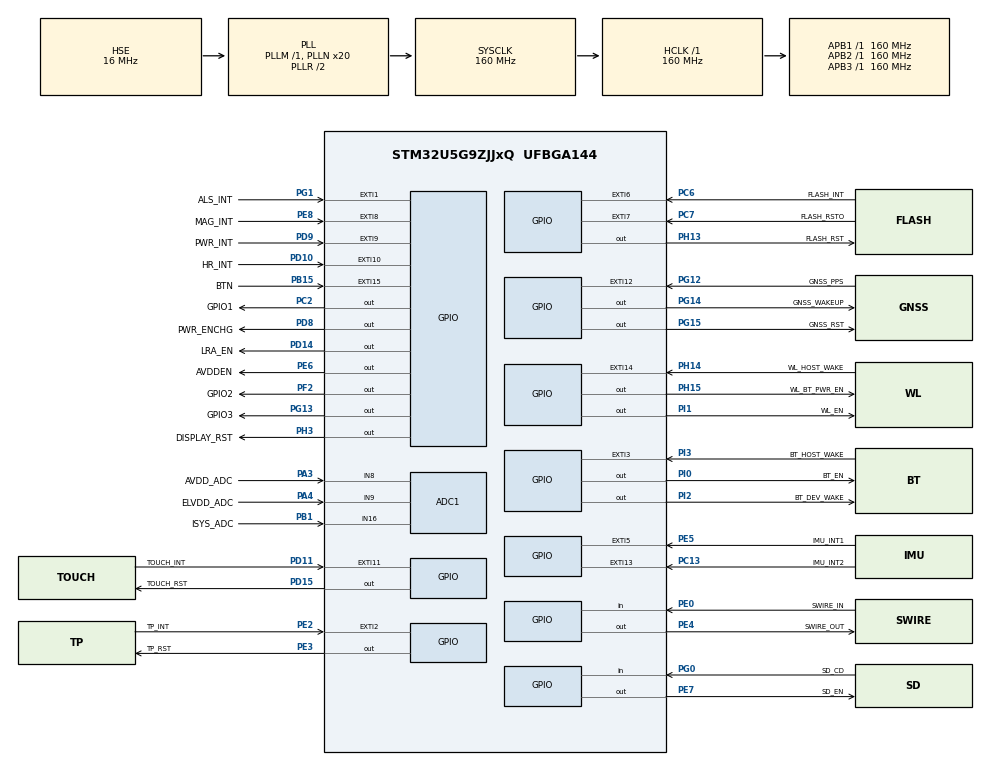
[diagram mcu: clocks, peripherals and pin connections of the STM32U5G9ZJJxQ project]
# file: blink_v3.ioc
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ADC1.Channel-0\#ChannelRegularConversion=ADC_CHANNEL_8
ADC1.MonitoredBy-0\#ChannelRegularConversion=__NULL
ADC1.NbrOfConversionFlag=1
ADC1.OffsetNumber-0\#ChannelRegularConversion=ADC_OFFSET_NONE
ADC1.Rank-0\#ChannelRegularConversion=1
ADC1.SamplingTime-0\#ChannelRegularConversion=ADC_SAMPLETIME_5CYCLE
ADC1.master=1
CORTEX_M33_NS.userName=CORTEX_M33
DSI_CKN.PinAttribute=Free
DSI_CKN.Signal=DSIHOST_CKN
DSI_CKP.PinAttribute=Free
DSI_CKP.Signal=DSIHOST_CKP
DSI_D0N.PinAttribute=Free
DSI_D0N.Signal=DSIHOST_D0N
DSI_D0P.PinAttribute=Free
DSI_D0P.Signal=DSIHOST_D0P
DSI_D1N.PinAttribute=Free
DSI_D1N.Signal=DSIHOST_D1N
DSI_D1P.PinAttribute=Free
DSI_D1P.Signal=DSIHOST_D1P
Mcu.Family=STM32U5
Mcu.Name=STM32U5G9ZJJxQ
Mcu.Package=UFBGA144
NVIC.PriorityGroup=NVIC_PRIORITYGROUP_4
NVIC.TIM6_IRQn=true\:15\:0\:false\:false\:true\:false\:true\:true
NVIC.TimeBase=TIM6_IRQn
NVIC.TimeBaseIP=TIM6
PA0.PinAttribute=Free
PA0.Signal=UART4_TX
PA1.PinAttribute=Free
PA1.Signal=UART4_RX
PA11.Signal=USB_OTG_HS_DM
PA12.Signal=USB_OTG_HS_DP
PA13\ (JTMS/SWDIO).Mode=Serial_Wire
PA13\ (JTMS/SWDIO).Signal=DEBUG_JTMS-SWDIO
PA14\ (JTCK/SWCLK).Mode=Serial_Wire
PA14\ (JTCK/SWCLK).Signal=DEBUG_JTCK-SWCLK
PA15\ (JTDI).Signal=USART2_RX
PA2.Mode=Clock-out-LSCO
PA2.Signal=RCC_LSCO
PA3.GPIO_Label=AVDD_ADC
PA3.Mode=IN8-Single-Ended
PA3.Signal=ADC1_IN8
PA4.GPIO_Label=ELVDD_ADC
PA4.Mode=IN9-Single-Ended
PA4.Signal=ADC1_IN9
PA5.PinAttribute=Free
PA5.Signal=SPI1_SCK
PA6.Signal=SPI1_MISO
PA7.Signal=SPI1_MOSI
PA8.Signal=SDMMC2_D1
PB0.PinAttribute=Free
PB0.Signal=SPI1_NSS
PB1.GPIO_Label=ISYS_ADC
PB1.Mode=IN16-Single-Ended
PB1.Signal=ADC1_IN16
PB10.Signal=OCTOSPIM_P1_CLK
PB11.PinAttribute=Free
PB11.Signal=I2C2_SDA
PB13.Signal=I2C2_SCL
PB14.PinAttribute=Free
PB14.Signal=SDMMC2_D0
PB15.GPIO_Label=BTN
PB15.Signal=GPXTI15
PB2.PinAttribute=Free
PB2.Signal=OCTOSPIM_P1_DQS
PB3\ (JTDO/TRACESWO).Signal=SDMMC2_D2
PB4\ (NJTRST).PinAttribute=Free
PB4\ (NJTRST).Signal=SDMMC2_D3
PB5.Signal=OCTOSPIM_P1_NCLK
PB6.PinAttribute=Free
PB6.Signal=I2C1_SCL
PB7.Signal=DSIHOST_TE
PB8.Signal=SDMMC1_CKIN
PB9.Signal=I2C1_SDA
PC0.PinAttribute=Free
PC0.Signal=I2C3_SCL
PC1.PinAttribute=Free
PC1.Signal=I2C3_SDA
PC10.Signal=SDMMC1_D2
PC11.Signal=SDMMC1_D3
PC12.PinAttribute=Free
PC12.Signal=SDMMC1_CK
PC13.GPIO_Label=IMU_INT2
PC13.PinAttribute=Free
PC13.Signal=GPXTI13
PC14-OSC32_IN\ (PC14).Mode=LSE-External-Oscillator
PC14-OSC32_IN\ (PC14).Signal=RCC_OSC32_IN
PC15-OSC32_OUT\ (PC15).Mode=LSE-External-Oscillator
PC15-OSC32_OUT\ (PC15).Signal=RCC_OSC32_OUT
PC2.GPIO_Label=GPIO1
PC2.PinAttribute=Free
PC2.Signal=GPIO_Output
PC3.GPIO_Label=ELVSS_ADC
PC3.Signal=ADC1_IN4
PC6.GPIO_Label=FLASH_INT
PC6.PinAttribute=Free
PC6.Signal=GPXTI6
PC7.GPIO_Label=FLASH_RSTO
PC7.PinAttribute=Free
PC7.Signal=GPXTI7
PC8.Signal=SDMMC1_D0
PC9.PinAttribute=Free
PC9.Signal=SDMMC1_D1
PD0.Signal=I2C5_SDA
PD1.PinAttribute=Free
PD1.Signal=I2C5_SCL
PD10.GPIO_Label=HR_INT
PD10.PinAttribute=Free
PD10.Signal=GPXTI10
PD11.GPIO_Label=TOUCH_INT
PD11.PinAttribute=Free
PD11.Signal=GPXTI11
PD12.Signal=I2C4_SCL
PD13.Signal=I2C4_SDA
PD14.GPIO_Label=LRA_EN
PD14.Signal=GPIO_Output
PD15.GPIO_Label=TOUCH_RST
PD15.GPIO_ModeDefaultOutputPP=GPIO_MODE_OUTPUT_OD
PD15.GPIO_PuPd=GPIO_NOPULL
PD15.PinAttribute=Free
PD15.Signal=GPIO_Output
PD2.Signal=SDMMC1_CMD
PD3.PinAttribute=Free
PD3.Signal=USART2_CTS
PD4.Signal=USART2_RTS
PD5.Signal=USART2_TX
PD6.Signal=SDMMC2_CK
PD7.PinAttribute=Free
PD7.Signal=SDMMC2_CMD
PD8.GPIO_Label=PWR_ENCHG
PD8.Signal=GPIO_Output
PD9.GPIO_Label=PWR_INT
PD9.Signal=GPXTI9
PE0.GPIO_Label=SWIRE_IN
PE0.PinAttribute=Free
PE0.Signal=GPIO_Input
PE10.PinAttribute=Free
PE10.Signal=ADF1_SDI0
PE11.Signal=OCTOSPIM_P1_NCS
PE12.PinAttribute=Free
PE12.Signal=OCTOSPIM_P1_IO0
PE13.Signal=OCTOSPIM_P1_IO1
PE14.PinAttribute=Free
PE14.Signal=OCTOSPIM_P1_IO2
PE15.Signal=OCTOSPIM_P1_IO3
PE2.GPIO_Label=TP_INT
PE2.PinAttribute=Free
PE2.Signal=GPXTI2
PE3.GPIO_Label=TP_RST
PE3.PinAttribute=Free
PE3.Signal=GPIO_Output
PE4.GPIO_Label=SWIRE_OUT
PE4.Signal=GPIO_Output
PE5.GPIO_Label=IMU_INT1
PE5.Signal=GPXTI5
PE6.GPIO_Label=AVDDEN
PE6.Signal=GPIO_Output
PE7.GPIO_Label=SD_EN
PE7.Signal=GPIO_Output
PE8.GPIO_Label=MAG_INT
PE8.PinAttribute=Free
PE8.Signal=GPXTI8
PE9.PinAttribute=Free
PE9.Signal=ADF1_CCK0
PF0.PinAttribute=Free
PF0.Signal=I2C6_SDA
PF1.PinAttribute=Free
PF1.Signal=I2C6_SCL
PF2.GPIO_Label=GPIO2
PF2.PinAttribute=Free
PF2.Signal=GPIO_Output
PG0.GPIO_Label=SD_CD
PG0.PinAttribute=Free
PG0.Signal=GPIO_Input
PG1.GPIO_Label=ALS_INT
PG1.PinAttribute=Free
PG1.Signal=GPXTI1
PG10.PinAttribute=Free
PG10.Signal=USART1_RX
PG12.GPIO_Label=GNSS_PPS
PG12.PinAttribute=Free
PG12.Signal=GPXTI12
PG13.GPIO_Label=GPIO3
PG13.Signal=GPIO_Output
PG14.GPIO_Label=GNSS_WAKEUP
PG14.PinAttribute=Free
PG14.Signal=GPIO_Output
PG15.GPIO_Label=GNSS_RST
PG15.Signal=GPIO_Output
PG9.Signal=USART1_TX
PH0-OSC_IN\ (PH0).Mode=HSE-External-Oscillator
PH0-OSC_IN\ (PH0).PinAttribute=Free
PH0-OSC_IN\ (PH0).Signal=RCC_OSC_IN
PH1-OSC_OUT\ (PH1).Mode=HSE-External-Oscillator
PH1-OSC_OUT\ (PH1).PinAttribute=Free
PH1-OSC_OUT\ (PH1).Signal=RCC_OSC_OUT
PH10.PinAttribute=Free
PH10.Signal=OCTOSPIM_P2_IO5
PH11.PinAttribute=Free
PH11.Signal=OCTOSPIM_P2_IO6
PH12.PinAttribute=Free
PH12.Signal=OCTOSPIM_P2_IO7
PH13.GPIO_Label=FLASH_RST
PH13.PinAttribute=Free
PH13.Signal=GPIO_Output
PH14.GPIO_Label=WL_HOST_WAKE
PH14.PinAttribute=Free
PH14.Signal=GPXTI14
PH15.GPIO_Label=WL_BT_PWR_EN
PH15.PinAttribute=Free
PH15.Signal=GPIO_Output
PH3-BOOT0.GPIO_Label=DISPLAY_RST
PH3-BOOT0.PinAttribute=Free
PH3-BOOT0.Signal=GPIO_Output
PH9.Signal=OCTOSPIM_P2_IO4
PI0.GPIO_Label=BT_EN
PI0.PinAttribute=Free
PI0.Signal=GPIO_Output
PI1.GPIO_Label=WL_EN
PI1.PinAttribute=Free
PI1.Signal=GPIO_Output
PI2.GPIO_Label=BT_DEV_WAKE
PI2.PinAttribute=Free
PI2.Signal=GPIO_Output
PI3.GPIO_Label=BT_HOST_WAKE
PI3.PinAttribute=Free
PI3.Signal=GPXTI3
PWR.PowerMode=PWR_SMPS_SUPPLY
ProjectManager.HeapSize=0x200
ProjectManager.StackSize=0x400
ProjectManager.TargetToolchain=STM32CubeIDE
RCC.ADCFreq_Value=16000000
RCC.AHBFreq_Value=160000000
RCC.APB1Freq_Value=160000000
RCC.APB1TimFreq_Value=160000000
RCC.APB2Freq_Value=160000000
RCC.APB2TimFreq_Value=160000000
RCC.APB3Freq_Value=160000000
RCC.CortexFreq_Value=160000000
RCC.EPOD_VALUE=16000000
RCC.FLatency=FLASH_LATENCY_2
RCC.HCLKFreq_Value=160000000
RCC.HSE_VALUE=16000000
RCC.HSI48_VALUE=48000000
RCC.HSI_VALUE=16000000
RCC.LSCOSource1Virtual=RCC_LSCOSOURCE_LSE
RCC.LSIDIV_VALUE=32000
RCC.MSI_VALUE=4000000
RCC.PLL2Source=RCC_PLLSOURCE_HSE
RCC.PLL3Source=RCC_PLLSOURCE_HSE
RCC.PLLN=20
RCC.PLLSourceVirtual=RCC_PLLSOURCE_HSE
RCC.RTCClockSelection=RCC_RTCCLKSOURCE_LSE
RCC.SYSCLKFreq_VALUE=160000000
RCC.SYSCLKSource=RCC_SYSCLKSOURCE_PLLCLK
RCC.VCOOutputFreq_Value=320000000
RCC.VDD_VALUE=1.8
VP_DCACHE1_VS_DCACHE.Mode=DCACHE_Activate
VP_DCACHE2_VS_DCACHE.Mode=DCACHE_Activate
VP_ICACHE_VS_ICACHE.Mode=DefaultMode
VP_LPBAMQUEUE_VS_QUEUE.Mode=QUEUEMODE
VP_LPBAM_VS_SIG1.Mode=SmartRun
VP_LPBAM_VS_SIG4.Mode=LPDMA1
VP_MEMORYMAP_VS_MEMORYMAP.Mode=CurAppReg
VP_PWR_VS_LPOM.Mode=PowerOptimisation
VP_PWR_VS_SECSignals.Mode=Security/Privilege
VP_PWR_Vdda.Mode=isolationVdda
VP_RTC_VS_RTC_Activate.Mode=RTC_Enabled
VP_SYS_VS_tim6.Mode=TIM6
VREF+.Mode=InternalMode
VREF+.PinAttribute=Free
VREF+.Signal=VREFBUF_OUT
board=custom

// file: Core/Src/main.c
/* USER CODE BEGIN Header */
/**
  ******************************************************************************
  * @file           : main.c
  * @brief          : Main program body
  ******************************************************************************
  * @attention
  *
  * Copyright (c) 2024 STMicroelectronics.
  * All rights reserved.
  *
  * This software is licensed under terms that can be found in the LICENSE file
  * in the root directory of this software component.
  * If no LICENSE file comes with this software, it is provided AS-IS.
  *
  ******************************************************************************
  */
/* USER CODE END Header */
#include "main.h"

ADC_HandleTypeDef hadc1;

DCACHE_HandleTypeDef hdcache1;
DCACHE_HandleTypeDef hdcache2;

RTC_HandleTypeDef hrtc;

void SystemClock_Config(void);
static void SystemPower_Config(void);
static void MX_GPIO_Init(void);
static void MX_DCACHE1_Init(void);
static void MX_DCACHE2_Init(void);
static void MX_ICACHE_Init(void);
static void MX_RTC_Init(void);
static void MX_ADC1_Init(void);

int main(void)
{

  /* MCU Configuration--------------------------------------------------------*/

  /* Reset of all peripherals, Initializes the Flash interface and the Systick. */
  HAL_Init();

  /* Configure the system clock */
  SystemClock_Config();

  /* Configure the System Power */
  SystemPower_Config();

  /* Initialize all configured peripherals */
  MX_GPIO_Init();
  MX_DCACHE1_Init();
  MX_DCACHE2_Init();
  MX_ICACHE_Init();
  MX_RTC_Init();
  MX_ADC1_Init();

  /* Infinite loop */
  /* USER CODE BEGIN WHILE */
  while (1)
  {
	  HAL_GPIO_TogglePin(GPIO1_GPIO_Port, GPIO1_Pin);
	  HAL_Delay(500);
    /* USER CODE END WHILE */

  }
}

void SystemClock_Config(void)
{
  RCC_OscInitTypeDef RCC_OscInitStruct = {0};
  RCC_ClkInitTypeDef RCC_ClkInitStruct = {0};

  /** Configure the main internal regulator output voltage
  */
  if (HAL_PWREx_ControlVoltageScaling(PWR_REGULATOR_VOLTAGE_SCALE1) != HAL_OK)
  {
    Error_Handler();
  }

  /** Configure LSE Drive Capability
  */
  HAL_PWR_EnableBkUpAccess();
  __HAL_RCC_LSEDRIVE_CONFIG(RCC_LSEDRIVE_LOW);

  /** Initializes the CPU, AHB and APB buses clocks
  */
  RCC_OscInitStruct.OscillatorType = RCC_OSCILLATORTYPE_HSI|RCC_OSCILLATORTYPE_HSE
                              |RCC_OSCILLATORTYPE_LSE;
  RCC_OscInitStruct.HSEState = RCC_HSE_ON;
  RCC_OscInitStruct.LSEState = RCC_LSE_ON;
  RCC_OscInitStruct.HSIState = RCC_HSI_ON;
  RCC_OscInitStruct.HSICalibrationValue = RCC_HSICALIBRATION_DEFAULT;
  RCC_OscInitStruct.PLL.PLLState = RCC_PLL_ON;
  RCC_OscInitStruct.PLL.PLLSource = RCC_PLLSOURCE_HSE;
  RCC_OscInitStruct.PLL.PLLMBOOST = RCC_PLLMBOOST_DIV1;
  RCC_OscInitStruct.PLL.PLLM = 1;
  RCC_OscInitStruct.PLL.PLLN = 20;
  RCC_OscInitStruct.PLL.PLLP = 2;
  RCC_OscInitStruct.PLL.PLLQ = 2;
  RCC_OscInitStruct.PLL.PLLR = 2;
  RCC_OscInitStruct.PLL.PLLRGE = RCC_PLLVCIRANGE_1;
  RCC_OscInitStruct.PLL.PLLFRACN = 0;
  if (HAL_RCC_OscConfig(&RCC_OscInitStruct) != HAL_OK)
  {
    Error_Handler();
  }

  /** Initializes the CPU, AHB and APB buses clocks
  */
  RCC_ClkInitStruct.ClockType = RCC_CLOCKTYPE_HCLK|RCC_CLOCKTYPE_SYSCLK
                              |RCC_CLOCKTYPE_PCLK1|RCC_CLOCKTYPE_PCLK2
                              |RCC_CLOCKTYPE_PCLK3;
  RCC_ClkInitStruct.SYSCLKSource = RCC_SYSCLKSOURCE_PLLCLK;
  RCC_ClkInitStruct.AHBCLKDivider = RCC_SYSCLK_DIV1;
  RCC_ClkInitStruct.APB1CLKDivider = RCC_HCLK_DIV1;
  RCC_ClkInitStruct.APB2CLKDivider = RCC_HCLK_DIV1;
  RCC_ClkInitStruct.APB3CLKDivider = RCC_HCLK_DIV1;

  if (HAL_RCC_ClockConfig(&RCC_ClkInitStruct, FLASH_LATENCY_2) != HAL_OK)
  {
    Error_Handler();
  }

  /** LSCO configuration
  */
  HAL_RCCEx_EnableLSCO(RCC_LSCOSOURCE_LSE);
}

/**
  * @brief Power Configuration
  * @retval None
  */
static void SystemPower_Config(void)
{
  HAL_PWREx_EnableVddIO2();

  /*
   * Switch to SMPS regulator instead of LDO
   */
  if (HAL_PWREx_ConfigSupply(PWR_SMPS_SUPPLY) != HAL_OK)
  {
    Error_Handler();
  }
}

static void MX_ADC1_Init(void)
{

  ADC_ChannelConfTypeDef sConfig = {0};

  /** Common config
  */
  hadc1.Instance = ADC1;
  hadc1.Init.ClockPrescaler = ADC_CLOCK_ASYNC_DIV1;
  hadc1.Init.Resolution = ADC_RESOLUTION_14B;
  hadc1.Init.GainCompensation = 0;
  hadc1.Init.DataAlign = ADC_DATAALIGN_RIGHT;
  hadc1.Init.ScanConvMode = ADC_SCAN_DISABLE;
  hadc1.Init.EOCSelection = ADC_EOC_SINGLE_CONV;
  hadc1.Init.LowPowerAutoWait = DISABLE;
  hadc1.Init.ContinuousConvMode = DISABLE;
  hadc1.Init.NbrOfConversion = 1;
  hadc1.Init.DiscontinuousConvMode = DISABLE;
  hadc1.Init.ExternalTrigConv = ADC_SOFTWARE_START;
  hadc1.Init.ExternalTrigConvEdge = ADC_EXTERNALTRIGCONVEDGE_NONE;
  hadc1.Init.DMAContinuousRequests = DISABLE;
  hadc1.Init.TriggerFrequencyMode = ADC_TRIGGER_FREQ_HIGH;
  hadc1.Init.Overrun = ADC_OVR_DATA_PRESERVED;
  hadc1.Init.LeftBitShift = ADC_LEFTBITSHIFT_NONE;
  hadc1.Init.ConversionDataManagement = ADC_CONVERSIONDATA_DR;
  hadc1.Init.OversamplingMode = DISABLE;
  if (HAL_ADC_Init(&hadc1) != HAL_OK)
  {
    Error_Handler();
  }

  /** Configure Regular Channel
  */
  sConfig.Channel = ADC_CHANNEL_8;
  sConfig.Rank = ADC_REGULAR_RANK_1;
  sConfig.SamplingTime = ADC_SAMPLETIME_5CYCLE;
  sConfig.SingleDiff = ADC_SINGLE_ENDED;
  sConfig.OffsetNumber = ADC_OFFSET_NONE;
  sConfig.Offset = 0;
  if (HAL_ADC_ConfigChannel(&hadc1, &sConfig) != HAL_OK)
  {
    Error_Handler();
  }

}

static void MX_DCACHE1_Init(void)
{

  hdcache1.Instance = DCACHE1;
  hdcache1.Init.ReadBurstType = DCACHE_READ_BURST_WRAP;
  if (HAL_DCACHE_Init(&hdcache1) != HAL_OK)
  {
    Error_Handler();
  }

}

static void MX_DCACHE2_Init(void)
{

  hdcache2.Instance = DCACHE2;
  hdcache2.Init.ReadBurstType = DCACHE_READ_BURST_WRAP;
  if (HAL_DCACHE_Init(&hdcache2) != HAL_OK)
  {
    Error_Handler();
  }
   __HAL_RCC_SYSCFG_CLK_ENABLE();
   HAL_SYSCFG_DisableSRAMCached();

}

static void MX_ICACHE_Init(void)
{

  /** Enable instruction cache (default 2-ways set associative cache)
  */
  if (HAL_ICACHE_Enable() != HAL_OK)
  {
    Error_Handler();
  }

}

static void MX_RTC_Init(void)
{

  RTC_PrivilegeStateTypeDef privilegeState = {0};

  /** Initialize RTC Only
  */
  hrtc.Instance = RTC;
  hrtc.Init.HourFormat = RTC_HOURFORMAT_24;
  hrtc.Init.AsynchPrediv = 127;
  hrtc.Init.SynchPrediv = 255;
  hrtc.Init.OutPut = RTC_OUTPUT_DISABLE;
  hrtc.Init.OutPutRemap = RTC_OUTPUT_REMAP_NONE;
  hrtc.Init.OutPutPolarity = RTC_OUTPUT_POLARITY_HIGH;
  hrtc.Init.OutPutType = RTC_OUTPUT_TYPE_OPENDRAIN;
  hrtc.Init.OutPutPullUp = RTC_OUTPUT_PULLUP_NONE;
  hrtc.Init.BinMode = RTC_BINARY_NONE;
  if (HAL_RTC_Init(&hrtc) != HAL_OK)
  {
    Error_Handler();
  }
  privilegeState.rtcPrivilegeFull = RTC_PRIVILEGE_FULL_NO;
  privilegeState.backupRegisterPrivZone = RTC_PRIVILEGE_BKUP_ZONE_NONE;
  privilegeState.backupRegisterStartZone2 = RTC_BKP_DR0;
  privilegeState.backupRegisterStartZone3 = RTC_BKP_DR0;
  if (HAL_RTCEx_PrivilegeModeSet(&hrtc, &privilegeState) != HAL_OK)
  {
    Error_Handler();
  }

}

static void MX_GPIO_Init(void)
{
  GPIO_InitTypeDef GPIO_InitStruct = {0};

  /* GPIO Ports Clock Enable */
  __HAL_RCC_GPIOB_CLK_ENABLE();
  __HAL_RCC_GPIOH_CLK_ENABLE();
  __HAL_RCC_GPIOG_CLK_ENABLE();
  __HAL_RCC_GPIOD_CLK_ENABLE();
  __HAL_RCC_GPIOC_CLK_ENABLE();
  __HAL_RCC_GPIOE_CLK_ENABLE();
  __HAL_RCC_GPIOA_CLK_ENABLE();
  __HAL_RCC_GPIOF_CLK_ENABLE();
  __HAL_RCC_GPIOI_CLK_ENABLE();

  /*Configure GPIO pin Output Level */
  HAL_GPIO_WritePin(GPIOH, DISPLAY_RST_Pin|WL_BT_PWR_EN_Pin|FLASH_RST_Pin, GPIO_PIN_RESET);

  /*Configure GPIO pin Output Level */
  HAL_GPIO_WritePin(GPIOG, GNSS_WAKEUP_Pin|GNSS_RST_Pin|GPIO3_Pin, GPIO_PIN_RESET);

  /*Configure GPIO pin Output Level */
  HAL_GPIO_WritePin(GPIOE, TP_RST_Pin|SWIRE_OUT_Pin|AVDDEN_Pin|SD_EN_Pin, GPIO_PIN_RESET);

  /*Configure GPIO pin Output Level */
  HAL_GPIO_WritePin(GPIOI, BT_DEV_WAKE_Pin|BT_EN_Pin|WL_EN_Pin, GPIO_PIN_RESET);

  /*Configure GPIO pin Output Level */
  HAL_GPIO_WritePin(GPIO2_GPIO_Port, GPIO2_Pin, GPIO_PIN_RESET);

  /*Configure GPIO pin Output Level */
  HAL_GPIO_WritePin(GPIO1_GPIO_Port, GPIO1_Pin, GPIO_PIN_RESET);

  /*Configure GPIO pin Output Level */
  HAL_GPIO_WritePin(GPIOD, TOUCH_RST_Pin|LRA_EN_Pin|PWR_ENCHG_Pin, GPIO_PIN_RESET);

  /*Configure GPIO pins : PB9 PB6 */
  GPIO_InitStruct.Pin = GPIO_PIN_9|GPIO_PIN_6;
  GPIO_InitStruct.Mode = GPIO_MODE_AF_OD;
  GPIO_InitStruct.Pull = GPIO_NOPULL;
  GPIO_InitStruct.Speed = GPIO_SPEED_FREQ_LOW;
  GPIO_InitStruct.Alternate = GPIO_AF4_I2C1;
  HAL_GPIO_Init(GPIOB, &GPIO_InitStruct);

  /*Configure GPIO pins : DISPLAY_RST_Pin WL_BT_PWR_EN_Pin FLASH_RST_Pin */
  GPIO_InitStruct.Pin = DISPLAY_RST_Pin|WL_BT_PWR_EN_Pin|FLASH_RST_Pin;
  GPIO_InitStruct.Mode = GPIO_MODE_OUTPUT_PP;
  GPIO_InitStruct.Pull = GPIO_NOPULL;
  GPIO_InitStruct.Speed = GPIO_SPEED_FREQ_LOW;
  HAL_GPIO_Init(GPIOH, &GPIO_InitStruct);

  /*Configure GPIO pins : PB4 PB3 PB14 */
  GPIO_InitStruct.Pin = GPIO_PIN_4|GPIO_PIN_3|GPIO_PIN_14;
  GPIO_InitStruct.Mode = GPIO_MODE_AF_PP;
  GPIO_InitStruct.Pull = GPIO_NOPULL;
  GPIO_InitStruct.Speed = GPIO_SPEED_FREQ_HIGH;
  GPIO_InitStruct.Alternate = GPIO_AF12_SDMMC2;
  HAL_GPIO_Init(GPIOB, &GPIO_InitStruct);

  /*Configure GPIO pins : GNSS_WAKEUP_Pin GNSS_RST_Pin GPIO3_Pin */
  GPIO_InitStruct.Pin = GNSS_WAKEUP_Pin|GNSS_RST_Pin|GPIO3_Pin;
  GPIO_InitStruct.Mode = GPIO_MODE_OUTPUT_PP;
  GPIO_InitStruct.Pull = GPIO_NOPULL;
  GPIO_InitStruct.Speed = GPIO_SPEED_FREQ_LOW;
  HAL_GPIO_Init(GPIOG, &GPIO_InitStruct);

  /*Configure GPIO pins : GNSS_PPS_Pin ALS_INT_Pin */
  GPIO_InitStruct.Pin = GNSS_PPS_Pin|ALS_INT_Pin;
  GPIO_InitStruct.Mode = GPIO_MODE_IT_RISING;
  GPIO_InitStruct.Pull = GPIO_NOPULL;
  HAL_GPIO_Init(GPIOG, &GPIO_InitStruct);

  /*Configure GPIO pins : PG10 PG9 */
  GPIO_InitStruct.Pin = GPIO_PIN_10|GPIO_PIN_9;
  GPIO_InitStruct.Mode = GPIO_MODE_AF_PP;
  GPIO_InitStruct.Pull = GPIO_NOPULL;
  GPIO_InitStruct.Speed = GPIO_SPEED_FREQ_LOW;
  GPIO_InitStruct.Alternate = GPIO_AF7_USART1;
  HAL_GPIO_Init(GPIOG, &GPIO_InitStruct);

  /*Configure GPIO pins : PD7 PD6 */
  GPIO_InitStruct.Pin = GPIO_PIN_7|GPIO_PIN_6;
  GPIO_InitStruct.Mode = GPIO_MODE_AF_PP;
  GPIO_InitStruct.Pull = GPIO_NOPULL;
  GPIO_InitStruct.Speed = GPIO_SPEED_FREQ_HIGH;
  GPIO_InitStruct.Alternate = GPIO_AF11_SDMMC2;
  HAL_GPIO_Init(GPIOD, &GPIO_InitStruct);

  /*Configure GPIO pins : PD3 PD5 PD4 */
  GPIO_InitStruct.Pin = GPIO_PIN_3|GPIO_PIN_5|GPIO_PIN_4;
  GPIO_InitStruct.Mode = GPIO_MODE_AF_PP;
  GPIO_InitStruct.Pull = GPIO_NOPULL;
  GPIO_InitStruct.Speed = GPIO_SPEED_FREQ_LOW;
  GPIO_InitStruct.Alternate = GPIO_AF7_USART2;
  HAL_GPIO_Init(GPIOD, &GPIO_InitStruct);

  /*Configure GPIO pins : PC12 PC10 PC11 PC8
                           PC9 */
  GPIO_InitStruct.Pin = GPIO_PIN_12|GPIO_PIN_10|GPIO_PIN_11|GPIO_PIN_8
                          |GPIO_PIN_9;
  GPIO_InitStruct.Mode = GPIO_MODE_AF_PP;
  GPIO_InitStruct.Pull = GPIO_NOPULL;
  GPIO_InitStruct.Speed = GPIO_SPEED_FREQ_HIGH;
  GPIO_InitStruct.Alternate = GPIO_AF12_SDMMC1;
  HAL_GPIO_Init(GPIOC, &GPIO_InitStruct);

  /*Configure GPIO pins : TP_INT_Pin IMU_INT1_Pin MAG_INT_Pin */
  GPIO_InitStruct.Pin = TP_INT_Pin|IMU_INT1_Pin|MAG_INT_Pin;
  GPIO_InitStruct.Mode = GPIO_MODE_IT_RISING;
  GPIO_InitStruct.Pull = GPIO_NOPULL;
  HAL_GPIO_Init(GPIOE, &GPIO_InitStruct);

  /*Configure GPIO pins : TP_RST_Pin SWIRE_OUT_Pin AVDDEN_Pin SD_EN_Pin */
  GPIO_InitStruct.Pin = TP_RST_Pin|SWIRE_OUT_Pin|AVDDEN_Pin|SD_EN_Pin;
  GPIO_InitStruct.Mode = GPIO_MODE_OUTPUT_PP;
  GPIO_InitStruct.Pull = GPIO_NOPULL;
  GPIO_InitStruct.Speed = GPIO_SPEED_FREQ_LOW;
  HAL_GPIO_Init(GPIOE, &GPIO_InitStruct);

  /*Configure GPIO pin : SWIRE_IN_Pin */
  GPIO_InitStruct.Pin = SWIRE_IN_Pin;
  GPIO_InitStruct.Mode = GPIO_MODE_INPUT;
  GPIO_InitStruct.Pull = GPIO_NOPULL;
  HAL_GPIO_Init(SWIRE_IN_GPIO_Port, &GPIO_InitStruct);

  /*Configure GPIO pin : PB8 */
  GPIO_InitStruct.Pin = GPIO_PIN_8;
  GPIO_InitStruct.Mode = GPIO_MODE_AF_PP;
  GPIO_InitStruct.Pull = GPIO_NOPULL;
  GPIO_InitStruct.Speed = GPIO_SPEED_FREQ_HIGH;
  GPIO_InitStruct.Alternate = GPIO_AF8_SDMMC1;
  HAL_GPIO_Init(GPIOB, &GPIO_InitStruct);

  /*Configure GPIO pin : PB5 */
  GPIO_InitStruct.Pin = GPIO_PIN_5;
  GPIO_InitStruct.Mode = GPIO_MODE_AF_PP;
  GPIO_InitStruct.Pull = GPIO_NOPULL;
  GPIO_InitStruct.Speed = GPIO_SPEED_FREQ_VERY_HIGH;
  GPIO_InitStruct.Alternate = GPIO_AF3_OCTOSPI1;
  HAL_GPIO_Init(GPIOB, &GPIO_InitStruct);

  /*Configure GPIO pin : PD2 */
  GPIO_InitStruct.Pin = GPIO_PIN_2;
  GPIO_InitStruct.Mode = GPIO_MODE_AF_PP;
  GPIO_InitStruct.Pull = GPIO_NOPULL;
  GPIO_InitStruct.Speed = GPIO_SPEED_FREQ_HIGH;
  GPIO_InitStruct.Alternate = GPIO_AF12_SDMMC1;
  HAL_GPIO_Init(GPIOD, &GPIO_InitStruct);

  /*Configure GPIO pin : PB7 */
  GPIO_InitStruct.Pin = GPIO_PIN_7;
  GPIO_InitStruct.Mode = GPIO_MODE_AF_PP;
  GPIO_InitStruct.Pull = GPIO_NOPULL;
  GPIO_InitStruct.Speed = GPIO_SPEED_FREQ_LOW;
  GPIO_InitStruct.Alternate = GPIO_AF11_DSI;
  HAL_GPIO_Init(GPIOB, &GPIO_InitStruct);

  /*Configure GPIO pin : PA15 */
  GPIO_InitStruct.Pin = GPIO_PIN_15;
  GPIO_InitStruct.Mode = GPIO_MODE_AF_PP;
  GPIO_InitStruct.Pull = GPIO_NOPULL;
  GPIO_InitStruct.Speed = GPIO_SPEED_FREQ_LOW;
  GPIO_InitStruct.Alternate = GPIO_AF3_USART2;
  HAL_GPIO_Init(GPIOA, &GPIO_InitStruct);

  /*Configure GPIO pins : PA12 PA11 */
  GPIO_InitStruct.Pin = GPIO_PIN_12|GPIO_PIN_11;
  GPIO_InitStruct.Mode = GPIO_MODE_AF_PP;
  GPIO_InitStruct.Pull = GPIO_NOPULL;
  GPIO_InitStruct.Speed = GPIO_SPEED_FREQ_LOW;
  HAL_GPIO_Init(GPIOA, &GPIO_InitStruct);

  /*Configure GPIO pins : PD0 PD1 */
  GPIO_InitStruct.Pin = GPIO_PIN_0|GPIO_PIN_1;
  GPIO_InitStruct.Mode = GPIO_MODE_AF_OD;
  GPIO_InitStruct.Pull = GPIO_NOPULL;
  GPIO_InitStruct.Speed = GPIO_SPEED_FREQ_LOW;
  GPIO_InitStruct.Alternate = GPIO_AF4_I2C5;
  HAL_GPIO_Init(GPIOD, &GPIO_InitStruct);

  /*Configure GPIO pin : PA8 */
  GPIO_InitStruct.Pin = GPIO_PIN_8;
  GPIO_InitStruct.Mode = GPIO_MODE_AF_PP;
  GPIO_InitStruct.Pull = GPIO_NOPULL;
  GPIO_InitStruct.Speed = GPIO_SPEED_FREQ_HIGH;
  GPIO_InitStruct.Alternate = GPIO_AF8_SDMMC2;
  HAL_GPIO_Init(GPIOA, &GPIO_InitStruct);

  /*Configure GPIO pins : IMU_INT2_Pin FLASH_RSTO_Pin FLASH_INT_Pin */
  GPIO_InitStruct.Pin = IMU_INT2_Pin|FLASH_RSTO_Pin|FLASH_INT_Pin;
  GPIO_InitStruct.Mode = GPIO_MODE_IT_RISING;
  GPIO_InitStruct.Pull = GPIO_NOPULL;
  HAL_GPIO_Init(GPIOC, &GPIO_InitStruct);

  /*Configure GPIO pins : PF0 PF1 */
  GPIO_InitStruct.Pin = GPIO_PIN_0|GPIO_PIN_1;
  GPIO_InitStruct.Mode = GPIO_MODE_AF_OD;
  GPIO_InitStruct.Pull = GPIO_NOPULL;
  GPIO_InitStruct.Speed = GPIO_SPEED_FREQ_LOW;
  GPIO_InitStruct.Alternate = GPIO_AF2_I2C6;
  HAL_GPIO_Init(GPIOF, &GPIO_InitStruct);

  /*Configure GPIO pins : BT_DEV_WAKE_Pin BT_EN_Pin WL_EN_Pin */
  GPIO_InitStruct.Pin = BT_DEV_WAKE_Pin|BT_EN_Pin|WL_EN_Pin;
  GPIO_InitStruct.Mode = GPIO_MODE_OUTPUT_PP;
  GPIO_InitStruct.Pull = GPIO_NOPULL;
  GPIO_InitStruct.Speed = GPIO_SPEED_FREQ_LOW;
  HAL_GPIO_Init(GPIOI, &GPIO_InitStruct);

  /*Configure GPIO pin : BT_HOST_WAKE_Pin */
  GPIO_InitStruct.Pin = BT_HOST_WAKE_Pin;
  GPIO_InitStruct.Mode = GPIO_MODE_IT_RISING;
  GPIO_InitStruct.Pull = GPIO_NOPULL;
  HAL_GPIO_Init(BT_HOST_WAKE_GPIO_Port, &GPIO_InitStruct);

  /*Configure GPIO pin : GPIO2_Pin */
  GPIO_InitStruct.Pin = GPIO2_Pin;
  GPIO_InitStruct.Mode = GPIO_MODE_OUTPUT_PP;
  GPIO_InitStruct.Pull = GPIO_NOPULL;
  GPIO_InitStruct.Speed = GPIO_SPEED_FREQ_LOW;
  HAL_GPIO_Init(GPIO2_GPIO_Port, &GPIO_InitStruct);

  /*Configure GPIO pin : GPIO1_Pin */
  GPIO_InitStruct.Pin = GPIO1_Pin;
  GPIO_InitStruct.Mode = GPIO_MODE_OUTPUT_PP;
  GPIO_InitStruct.Pull = GPIO_NOPULL;
  GPIO_InitStruct.Speed = GPIO_SPEED_FREQ_LOW;
  HAL_GPIO_Init(GPIO1_GPIO_Port, &GPIO_InitStruct);

  /*Configure GPIO pin : WL_HOST_WAKE_Pin */
  GPIO_InitStruct.Pin = WL_HOST_WAKE_Pin;
  GPIO_InitStruct.Mode = GPIO_MODE_IT_RISING;
  GPIO_InitStruct.Pull = GPIO_NOPULL;
  HAL_GPIO_Init(WL_HOST_WAKE_GPIO_Port, &GPIO_InitStruct);

  /*Configure GPIO pins : PA0 PA1 */
  GPIO_InitStruct.Pin = GPIO_PIN_0|GPIO_PIN_1;
  GPIO_InitStruct.Mode = GPIO_MODE_AF_PP;
  GPIO_InitStruct.Pull = GPIO_NOPULL;
  GPIO_InitStruct.Speed = GPIO_SPEED_FREQ_LOW;
  GPIO_InitStruct.Alternate = GPIO_AF8_UART4;
  HAL_GPIO_Init(GPIOA, &GPIO_InitStruct);

  /*Configure GPIO pins : PB2 PB10 */
  GPIO_InitStruct.Pin = GPIO_PIN_2|GPIO_PIN_10;
  GPIO_InitStruct.Mode = GPIO_MODE_AF_PP;
  GPIO_InitStruct.Pull = GPIO_NOPULL;
  GPIO_InitStruct.Speed = GPIO_SPEED_FREQ_VERY_HIGH;
  GPIO_InitStruct.Alternate = GPIO_AF10_OCTOSPI1;
  HAL_GPIO_Init(GPIOB, &GPIO_InitStruct);

  /*Configure GPIO pin : TOUCH_RST_Pin */
  GPIO_InitStruct.Pin = TOUCH_RST_Pin;
  GPIO_InitStruct.Mode = GPIO_MODE_OUTPUT_OD;
  GPIO_InitStruct.Pull = GPIO_NOPULL;
  GPIO_InitStruct.Speed = GPIO_SPEED_FREQ_LOW;
  HAL_GPIO_Init(TOUCH_RST_GPIO_Port, &GPIO_InitStruct);

  /*Configure GPIO pins : PH12 PH11 PH10 PH9 */
  GPIO_InitStruct.Pin = GPIO_PIN_12|GPIO_PIN_11|GPIO_PIN_10|GPIO_PIN_9;
  GPIO_InitStruct.Mode = GPIO_MODE_AF_PP;
  GPIO_InitStruct.Pull = GPIO_NOPULL;
  GPIO_InitStruct.Speed = GPIO_SPEED_FREQ_VERY_HIGH;
  GPIO_InitStruct.Alternate = GPIO_AF5_OCTOSPI2;
  HAL_GPIO_Init(GPIOH, &GPIO_InitStruct);

  /*Configure GPIO pin : PB0 */
  GPIO_InitStruct.Pin = GPIO_PIN_0;
  GPIO_InitStruct.Mode = GPIO_MODE_AF_PP;
  GPIO_InitStruct.Pull = GPIO_NOPULL;
  GPIO_InitStruct.Speed = GPIO_SPEED_FREQ_LOW;
  GPIO_InitStruct.Alternate = GPIO_AF5_SPI1;
  HAL_GPIO_Init(GPIOB, &GPIO_InitStruct);

  /*Configure GPIO pins : PE10 PE9 */
  GPIO_InitStruct.Pin = GPIO_PIN_10|GPIO_PIN_9;
  GPIO_InitStruct.Mode = GPIO_MODE_AF_PP;
  GPIO_InitStruct.Pull = GPIO_NOPULL;
  GPIO_InitStruct.Speed = GPIO_SPEED_FREQ_LOW;
  GPIO_InitStruct.Alternate = GPIO_AF3_ADF1;
  HAL_GPIO_Init(GPIOE, &GPIO_InitStruct);

  /*Configure GPIO pins : PE12 PE14 PE13 PE11
                           PE15 */
  GPIO_InitStruct.Pin = GPIO_PIN_12|GPIO_PIN_14|GPIO_PIN_13|GPIO_PIN_11
                          |GPIO_PIN_15;
  GPIO_InitStruct.Mode = GPIO_MODE_AF_PP;
  GPIO_InitStruct.Pull = GPIO_NOPULL;
  GPIO_InitStruct.Speed = GPIO_SPEED_FREQ_VERY_HIGH;
  GPIO_InitStruct.Alternate = GPIO_AF10_OCTOSPI1;
  HAL_GPIO_Init(GPIOE, &GPIO_InitStruct);

  /*Configure GPIO pins : PC1 PC0 */
  GPIO_InitStruct.Pin = GPIO_PIN_1|GPIO_PIN_0;
  GPIO_InitStruct.Mode = GPIO_MODE_AF_OD;
  GPIO_InitStruct.Pull = GPIO_NOPULL;
  GPIO_InitStruct.Speed = GPIO_SPEED_FREQ_LOW;
  GPIO_InitStruct.Alternate = GPIO_AF4_I2C3;
  HAL_GPIO_Init(GPIOC, &GPIO_InitStruct);

  /*Configure GPIO pins : PA5 PA7 PA6 */
  GPIO_InitStruct.Pin = GPIO_PIN_5|GPIO_PIN_7|GPIO_PIN_6;
  GPIO_InitStruct.Mode = GPIO_MODE_AF_PP;
  GPIO_InitStruct.Pull = GPIO_NOPULL;
  GPIO_InitStruct.Speed = GPIO_SPEED_FREQ_LOW;
  GPIO_InitStruct.Alternate = GPIO_AF5_SPI1;
  HAL_GPIO_Init(GPIOA, &GPIO_InitStruct);

  /*Configure GPIO pin : SD_CD_Pin */
  GPIO_InitStruct.Pin = SD_CD_Pin;
  GPIO_InitStruct.Mode = GPIO_MODE_INPUT;
  GPIO_InitStruct.Pull = GPIO_NOPULL;
  HAL_GPIO_Init(SD_CD_GPIO_Port, &GPIO_InitStruct);

  /*Configure GPIO pins : PD13 PD12 */
  GPIO_InitStruct.Pin = GPIO_PIN_13|GPIO_PIN_12;
  GPIO_InitStruct.Mode = GPIO_MODE_AF_OD;
  GPIO_InitStruct.Pull = GPIO_NOPULL;
  GPIO_InitStruct.Speed = GPIO_SPEED_FREQ_LOW;
  GPIO_InitStruct.Alternate = GPIO_AF4_I2C4;
  HAL_GPIO_Init(GPIOD, &GPIO_InitStruct);

  /*Configure GPIO pins : PWR_INT_Pin TOUCH_INT_Pin HR_INT_Pin */
  GPIO_InitStruct.Pin = PWR_INT_Pin|TOUCH_INT_Pin|HR_INT_Pin;
  GPIO_InitStruct.Mode = GPIO_MODE_IT_RISING;
  GPIO_InitStruct.Pull = GPIO_NOPULL;
  HAL_GPIO_Init(GPIOD, &GPIO_InitStruct);

  /*Configure GPIO pin : PA2 */
  GPIO_InitStruct.Pin = GPIO_PIN_2;
  GPIO_InitStruct.Mode = GPIO_MODE_ANALOG;
  GPIO_InitStruct.Pull = GPIO_NOPULL;
  HAL_GPIO_Init(GPIOA, &GPIO_InitStruct);

  /*Configure GPIO pins : PB11 PB13 */
  GPIO_InitStruct.Pin = GPIO_PIN_11|GPIO_PIN_13;
  GPIO_InitStruct.Mode = GPIO_MODE_AF_OD;
  GPIO_InitStruct.Pull = GPIO_NOPULL;
  GPIO_InitStruct.Speed = GPIO_SPEED_FREQ_LOW;
  GPIO_InitStruct.Alternate = GPIO_AF4_I2C2;
  HAL_GPIO_Init(GPIOB, &GPIO_InitStruct);

  /*Configure GPIO pins : LRA_EN_Pin PWR_ENCHG_Pin */
  GPIO_InitStruct.Pin = LRA_EN_Pin|PWR_ENCHG_Pin;
  GPIO_InitStruct.Mode = GPIO_MODE_OUTPUT_PP;
  GPIO_InitStruct.Pull = GPIO_NOPULL;
  GPIO_InitStruct.Speed = GPIO_SPEED_FREQ_LOW;
  HAL_GPIO_Init(GPIOD, &GPIO_InitStruct);

  /*Configure GPIO pin : BTN_Pin */
  GPIO_InitStruct.Pin = BTN_Pin;
  GPIO_InitStruct.Mode = GPIO_MODE_IT_RISING;
  GPIO_InitStruct.Pull = GPIO_NOPULL;
  HAL_GPIO_Init(BTN_GPIO_Port, &GPIO_InitStruct);

}

void HAL_TIM_PeriodElapsedCallback(TIM_HandleTypeDef *htim)
{
  if (htim->Instance == TIM6) {
    HAL_IncTick();
  }
}

void Error_Handler(void)
{
  __disable_irq();
  while (1)
  {
  }
}
